AUTOSAR XML (schema 4-2-2)
package /AUTOLIV/SoftwareComponents/ATM
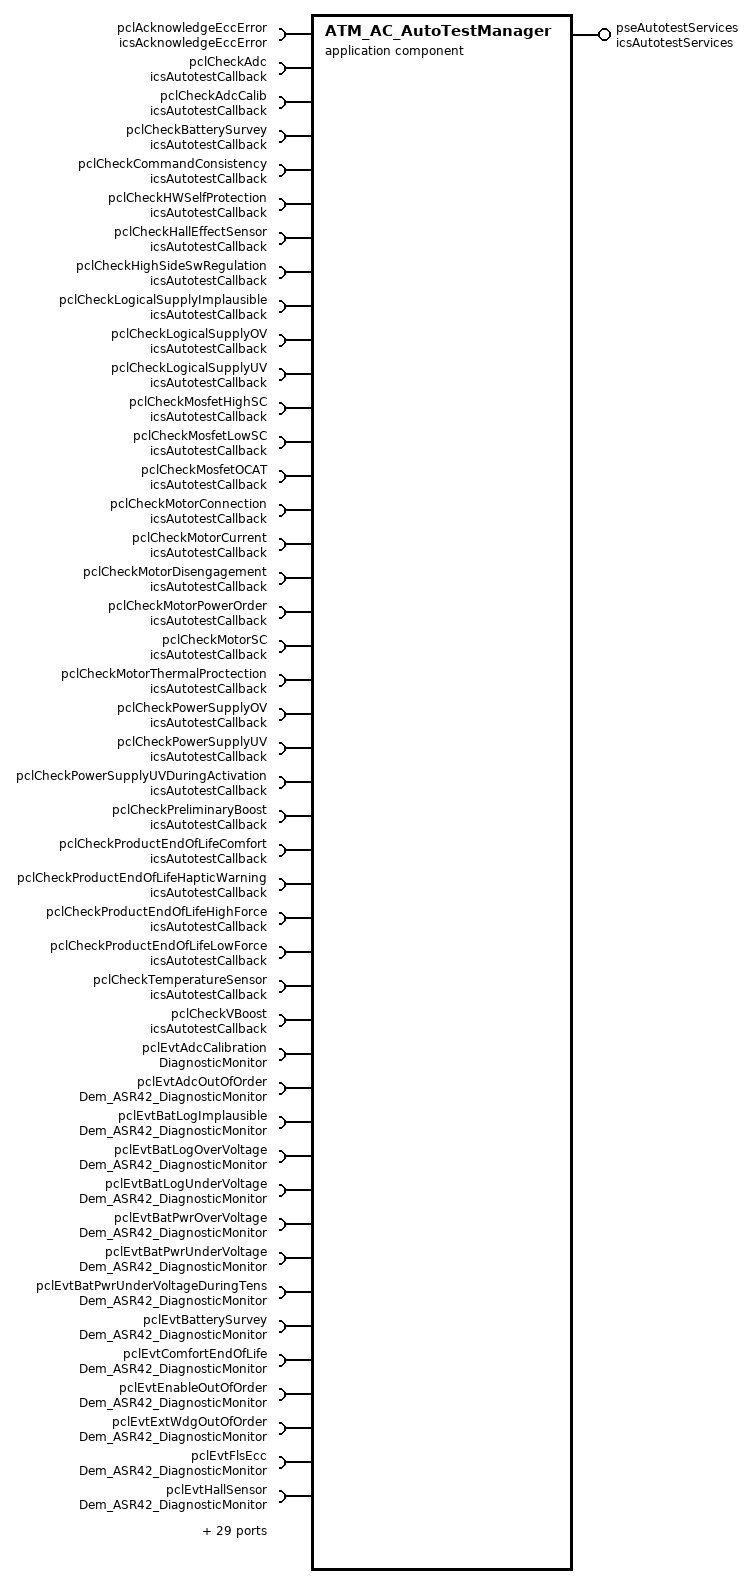
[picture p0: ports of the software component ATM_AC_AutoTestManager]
  application sw component type ATM_AC_AutoTestManager: category=SWC
    73 x require port:
      pclAcknowledgeEccError: client-com-spec=AcknowledgeEccError, required-interface=icsAcknowledgeEccError  # Port to acknowledge ECC error status
      pclCheckAdc: client-com-spec=AutotestCallback, required-interface=icsAutotestCallback
      pclCheckAdcCalib: client-com-spec=AutotestCallback, required-interface=icsAutotestCallback
      pclCheckBatterySurvey: client-com-spec=AutotestCallback, required-interface=icsAutotestCallback
      pclCheckCommandConsistency: client-com-spec=AutotestCallback, required-interface=icsAutotestCallback
      pclCheckHWSelfProtection: client-com-spec=AutotestCallback, required-interface=icsAutotestCallback
      pclCheckHallEffectSensor: client-com-spec=AutotestCallback, required-interface=icsAutotestCallback
      pclCheckHighSideSwRegulation: client-com-spec=AutotestCallback, required-interface=icsAutotestCallback
      pclCheckLogicalSupplyImplausible: client-com-spec=AutotestCallback, required-interface=icsAutotestCallback
      pclCheckLogicalSupplyOV: client-com-spec=AutotestCallback, required-interface=icsAutotestCallback
      pclCheckLogicalSupplyUV: client-com-spec=AutotestCallback, required-interface=icsAutotestCallback
      pclCheckMosfetHighSC: client-com-spec=AutotestCallback, required-interface=icsAutotestCallback
      pclCheckMosfetLowSC: client-com-spec=AutotestCallback, required-interface=icsAutotestCallback
      pclCheckMosfetOCAT: client-com-spec=AutotestCallback, required-interface=icsAutotestCallback
      pclCheckMotorConnection: client-com-spec=AutotestCallback, required-interface=icsAutotestCallback
      pclCheckMotorCurrent: client-com-spec=AutotestCallback, required-interface=icsAutotestCallback
      pclCheckMotorDisengagement: client-com-spec=AutotestCallback, required-interface=icsAutotestCallback
      pclCheckMotorPowerOrder: client-com-spec=AutotestCallback, required-interface=icsAutotestCallback
      pclCheckMotorSC: client-com-spec=AutotestCallback, required-interface=icsAutotestCallback
      pclCheckMotorThermalProctection: client-com-spec=AutotestCallback, required-interface=icsAutotestCallback
      pclCheckPowerSupplyOV: client-com-spec=AutotestCallback, required-interface=icsAutotestCallback
      pclCheckPowerSupplyUV: client-com-spec=AutotestCallback, required-interface=icsAutotestCallback
      pclCheckPowerSupplyUVDuringActivation: client-com-spec=AutotestCallback, required-interface=icsAutotestCallback
      pclCheckPreliminaryBoost: client-com-spec=AutotestCallback, required-interface=icsAutotestCallback
      pclCheckProductEndOfLifeComfort: client-com-spec=AutotestCallback, required-interface=icsAutotestCallback
      pclCheckProductEndOfLifeHapticWarning: client-com-spec=AutotestCallback, required-interface=icsAutotestCallback
      pclCheckProductEndOfLifeHighForce: client-com-spec=AutotestCallback, required-interface=icsAutotestCallback
      pclCheckProductEndOfLifeLowForce: client-com-spec=AutotestCallback, required-interface=icsAutotestCallback
      pclCheckTemperatureSensor: client-com-spec=AutotestCallback, required-interface=icsAutotestCallback
      pclCheckVBoost: client-com-spec=AutotestCallback, required-interface=icsAutotestCallback
      pclEvtAdcCalibration: required-com-specs=[SetEventStatus, ResetEventStatus, ResetEventDebounceStatus, PrestoreFreezeFrame, ClearPrestoredFreezeFrame], required-interface=DiagnosticMonitor
      pclEvtAdcOutOfOrder: required-com-specs=[SetEventStatus, ResetEventStatus, PrestoreFreezeFrame, ClearPrestoredFreezeFrame], required-interface=Dem_ASR42_DiagnosticMonitor
      pclEvtBatLogImplausible: required-com-specs=[SetEventStatus, ResetEventStatus, PrestoreFreezeFrame, ClearPrestoredFreezeFrame], required-interface=Dem_ASR42_DiagnosticMonitor
      pclEvtBatLogOverVoltage: required-com-specs=[SetEventStatus, ResetEventStatus, PrestoreFreezeFrame, ClearPrestoredFreezeFrame], required-interface=Dem_ASR42_DiagnosticMonitor
      pclEvtBatLogUnderVoltage: required-com-specs=[SetEventStatus, ResetEventStatus, PrestoreFreezeFrame, ClearPrestoredFreezeFrame], required-interface=Dem_ASR42_DiagnosticMonitor
      pclEvtBatPwrOverVoltage: required-com-specs=[SetEventStatus, ResetEventStatus, PrestoreFreezeFrame, ClearPrestoredFreezeFrame], required-interface=Dem_ASR42_DiagnosticMonitor
      pclEvtBatPwrUnderVoltage: required-com-specs=[SetEventStatus, ResetEventStatus, PrestoreFreezeFrame, ClearPrestoredFreezeFrame], required-interface=Dem_ASR42_DiagnosticMonitor
      pclEvtBatPwrUnderVoltageDuringTens: required-com-specs=[SetEventStatus, ResetEventStatus, PrestoreFreezeFrame, ClearPrestoredFreezeFrame], required-interface=Dem_ASR42_DiagnosticMonitor
      pclEvtBatterySurvey: required-com-specs=[SetEventStatus, ResetEventStatus, PrestoreFreezeFrame, ClearPrestoredFreezeFrame], required-interface=Dem_ASR42_DiagnosticMonitor
      pclEvtComfortEndOfLife: required-com-specs=[SetEventStatus, ResetEventStatus, PrestoreFreezeFrame, ClearPrestoredFreezeFrame], required-interface=Dem_ASR42_DiagnosticMonitor
      pclEvtEnableOutOfOrder: required-com-specs=[SetEventStatus, ResetEventStatus, PrestoreFreezeFrame, ClearPrestoredFreezeFrame], required-interface=Dem_ASR42_DiagnosticMonitor
      pclEvtExtWdgOutOfOrder: required-com-specs=[SetEventStatus, ResetEventStatus, PrestoreFreezeFrame, ClearPrestoredFreezeFrame], required-interface=Dem_ASR42_DiagnosticMonitor
      pclEvtFlsEcc: required-com-specs=[SetEventStatus, ResetEventStatus, PrestoreFreezeFrame, ClearPrestoredFreezeFrame], required-interface=Dem_ASR42_DiagnosticMonitor
      pclEvtHallSensor: required-com-specs=[SetEventStatus, ResetEventStatus, PrestoreFreezeFrame, ClearPrestoredFreezeFrame], required-interface=Dem_ASR42_DiagnosticMonitor
      pclEvtHapticWarningEndOfLife: required-com-specs=[SetEventStatus, ResetEventStatus, PrestoreFreezeFrame, ClearPrestoredFreezeFrame], required-interface=Dem_ASR42_DiagnosticMonitor
      pclEvtHighForceEndOfLife: required-com-specs=[SetEventStatus, ResetEventStatus, PrestoreFreezeFrame, ClearPrestoredFreezeFrame], required-interface=Dem_ASR42_DiagnosticMonitor
      pclEvtHighSideSwitch: required-com-specs=[SetEventStatus, ResetEventStatus, PrestoreFreezeFrame, ClearPrestoredFreezeFrame], required-interface=Dem_ASR42_DiagnosticMonitor
      pclEvtHwSelfProtection: required-com-specs=[SetEventStatus, ResetEventStatus, PrestoreFreezeFrame, ClearPrestoredFreezeFrame], required-interface=Dem_ASR42_DiagnosticMonitor
      pclEvtLowForceEndOfLife: required-com-specs=[SetEventStatus, ResetEventStatus, PrestoreFreezeFrame, ClearPrestoredFreezeFrame], required-interface=Dem_ASR42_DiagnosticMonitor
      pclEvtMosfetHighSc: required-com-specs=[SetEventStatus, ResetEventStatus, PrestoreFreezeFrame, ClearPrestoredFreezeFrame], required-interface=Dem_ASR42_DiagnosticMonitor
      pclEvtMosfetLowSc: required-com-specs=[SetEventStatus, ResetEventStatus, PrestoreFreezeFrame, ClearPrestoredFreezeFrame], required-interface=Dem_ASR42_DiagnosticMonitor
      pclEvtMosfetOc: required-com-specs=[SetEventStatus, ResetEventStatus, PrestoreFreezeFrame, ClearPrestoredFreezeFrame], required-interface=Dem_ASR42_DiagnosticMonitor
      pclEvtMotorBlocked: required-com-specs=[SetEventStatus, ResetEventStatus, PrestoreFreezeFrame, ClearPrestoredFreezeFrame], required-interface=Dem_ASR42_DiagnosticMonitor
      pclEvtMotorCurrent: required-com-specs=[SetEventStatus, ResetEventStatus, PrestoreFreezeFrame, ClearPrestoredFreezeFrame], required-interface=Dem_ASR42_DiagnosticMonitor
      pclEvtMotorDisconnected: required-com-specs=[SetEventStatus, ResetEventStatus, PrestoreFreezeFrame, ClearPrestoredFreezeFrame], required-interface=Dem_ASR42_DiagnosticMonitor
      pclEvtMotorInSc: required-com-specs=[SetEventStatus, ResetEventStatus, PrestoreFreezeFrame, ClearPrestoredFreezeFrame], required-interface=Dem_ASR42_DiagnosticMonitor
      pclEvtMotorOrder: required-com-specs=[SetEventStatus, ResetEventStatus, PrestoreFreezeFrame, ClearPrestoredFreezeFrame], required-interface=Dem_ASR42_DiagnosticMonitor
      pclEvtNvmEcc: required-com-specs=[SetEventStatus, ResetEventStatus, PrestoreFreezeFrame, ClearPrestoredFreezeFrame], required-interface=Dem_ASR42_DiagnosticMonitor
      pclEvtNvmNotPrg: required-com-specs=[SetEventStatus, ResetEventStatus, PrestoreFreezeFrame, ClearPrestoredFreezeFrame], required-interface=Dem_ASR42_DiagnosticMonitor
      pclEvtPowerBooster: required-com-specs=[SetEventStatus, ResetEventStatus, PrestoreFreezeFrame, ClearPrestoredFreezeFrame], required-interface=Dem_ASR42_DiagnosticMonitor
      pclEvtPreliminaryBooster: required-com-specs=[SetEventStatus, ResetEventStatus, PrestoreFreezeFrame, ClearPrestoredFreezeFrame], required-interface=Dem_ASR42_DiagnosticMonitor
      pclEvtRamEcc: required-com-specs=[SetEventStatus, ResetEventStatus, PrestoreFreezeFrame, ClearPrestoredFreezeFrame], required-interface=Dem_ASR42_DiagnosticMonitor
      pclEvtSwSelfProtection: required-com-specs=[SetEventStatus, ResetEventStatus, PrestoreFreezeFrame, ClearPrestoredFreezeFrame], required-interface=Dem_ASR42_DiagnosticMonitor
      pclEvtTemperatureSensorFailure: required-com-specs=[SetEventStatus, ResetEventStatus, PrestoreFreezeFrame, ClearPrestoredFreezeFrame], required-interface=Dem_ASR42_DiagnosticMonitor
      pclEvtWarmReset: required-com-specs=[SetEventStatus, ResetEventStatus, PrestoreFreezeFrame, ClearPrestoredFreezeFrame], required-interface=Dem_ASR42_DiagnosticMonitor
      pclGetEccErrorStatus: client-com-spec=GetEccError, required-interface=icsEccError  # Port to get ECC error status
      pclModeManagement: client-com-spec=CheckModeStatus, required-interface=icsModeManagement
      pclRunEepromMemoryCorruption: client-com-spec=AutotestCallback, required-interface=icsAutotestCallback
      pclRunEepromMemoryNotProgrammed: client-com-spec=AutotestCallback, required-interface=icsAutotestCallback
      pclRunPFlashMemoryCorruption: client-com-spec=AutotestCallback, required-interface=icsAutotestCallback
      pclRunRamMemoryCorruption: client-com-spec=AutotestCallback, required-interface=icsAutotestCallback
      pclRunResetCause: client-com-spec=AutotestCallback, required-interface=icsAutotestCallback
      pclRunTFlashMemoryCorruption: client-com-spec=AutotestCallback, required-interface=icsAutotestCallback
    provide port pseAutotestServices: provided-com-specs=[{operation=GetTestResult, queue-length=1}, {operation=GetLastCriticalAutotestID, queue-length=1}], provided-interface=icsAutotestServices
